# ipe5_target_db register map
Vendor: Texas Instruments
Address unit: 16 bits
Registers are 32-bit, access per field, reset 0x0 unless marked. A register's access mark holds for its fields unless they carry their own. Offsets are as the file gives them; [hi:lo] are bit positions; {n}, {i} and the like mark numbered series; 'fields as' and 'values as' point back to an identical list; <NAME> marks a mode.

## DSS (part 2 of 2) — ipxact12_to_ccs_generated
0x00 __ALL___SL2_BUF_ADDR_ORG_RASTER_TILED_LUMA_TOP — SL2 base address for RASTER OR TILED original pixels Luma location. For progressive, this MMR indicates the base address for Luma data. For interlaced frame and interlaced top field, this MMR indicates the base address for top field Luma data. For interlaced bottom field, this MMR indicates the base address for bottom field Luma data.
  [21:0] ADDR rw — SL2 Address for original pixels.
0x04 __ALL___SL2_BUF_ADDR_ORG_RASTER_TILED_CHROMA_TOP — SL2 base address for RASTER OR TILED original pixels Chroma location. For progressive, this MMR indicates the base address for Chroma data. For interlaced frame and interlaced top field, this MMR indicates the base address for top field Chroma data. For interlaced bottom field, this MMR indicates the base address for bottom field Chroma data.
  [21:0] ADDR rw — SL2 Address for original pixels.
0x08 __ALL___SL2_BUF_ADDR_ORG_RASTER_TILED_LUMA_BOT — SL2 base address for RASTER OR TILED original pixels Luma location. For progressive and interlaced field, this MMR is ignored. For interlaced frame, this MMR indicates the base address for bottom field Luma data.
  [21:0] ADDR rw — SL2 Address for original pixels.
0x0C __ALL___SL2_BUF_ADDR_ORG_RASTER_TILED_CHROMA_BOT — SL2 base address for RASTER OR TILED original pixels Chroma location. For progressive and interlaced field, this MMR is ignored. For interlaced frame, this MMR indicates the base address for bottom field Chroma data.
  [21:0] ADDR rw — SL2 Address for original pixels.
0x10 __ALL___SL2_BUF_ADDR_ORG_LUMA_TOP — SL2 base address for TILED original pixels Luma location updated by IPE5-PRE. For progressive, this MMR indicates the base address for Luma data. For interlaced frame and interlaced top field, this MMR indicates the base address for top field Luma data. For interlaced bottom field, this MMR indicates the base address for bottom field Luma data.
  [21:0] ADDR rw — SL2 Address for original pixels.
0x14 __ALL___SL2_BUF_ADDR_ORG_CHROMA_TOP — SL2 base address for TILED original pixels Chroma location updated by IPE5-PRE. For progressive, this MMR indicates the base address for Chroma data. For interlaced frame and interlaced top field, this MMR indicates the base address for top field Chroma data. For interlaced bottom field, this MMR indicates the base address for bottom field Chroma data.
  [21:0] ADDR rw — SL2 Address for original pixels.
0x18 __ALL___SL2_BUF_ADDR_ORG_LUMA_BOT — SL2 base address for TILED original pixels Luma location updated by IPE5-PRE. For progressive and interlaced field, this MMR is ignored. For interlaced frame, this MMR indicates the base address for bottom field Luma data.
  [21:0] ADDR rw — SL2 Address for original pixels.
0x1C __ALL___SL2_BUF_ADDR_ORG_CHROMA_BOT — SL2 base address for TILED original pixels Chroma location updated by IPE5-PRE. For progressive and interlaced field, this MMR is ignored. For interlaced frame, this MMR indicates the base address for bottom field Chroma data.
  [21:0] ADDR rw — SL2 Address for original pixels.
0x20 __ALL___SL2_BUF_ADDR_RECON_TOPLINE — SL2 base address for reference pixels location.
  [21:0] ADDR rw — SL2 Address for reference pixels.
0x24 __ALL___SL2_BUF_ADDR_ACTIVITYINFO — SL2 base address for writing out activity-info per MB.
  [21:0] ADDR rw — SL2 Address of activity-info location.
0x28 __ALL___SL2_BUF_ADDR_SLICEINFO_R — SL2 base address for reading initial slice info prepared by iCONT.
  [21:0] ADDR rw — SL2 Address.
0x2C __ALL___SL2_BUF_ADDR_SLICEINFO_W — SL2 base address for writing slice info.
  [21:0] ADDR rw — SL2 Address.
0x30 __ALL___SL2_BUF_ADDR_MBHDRINFO_TOP — SL2 base address for writing MB info.
  [21:0] ADDR rw — SL2 Address.
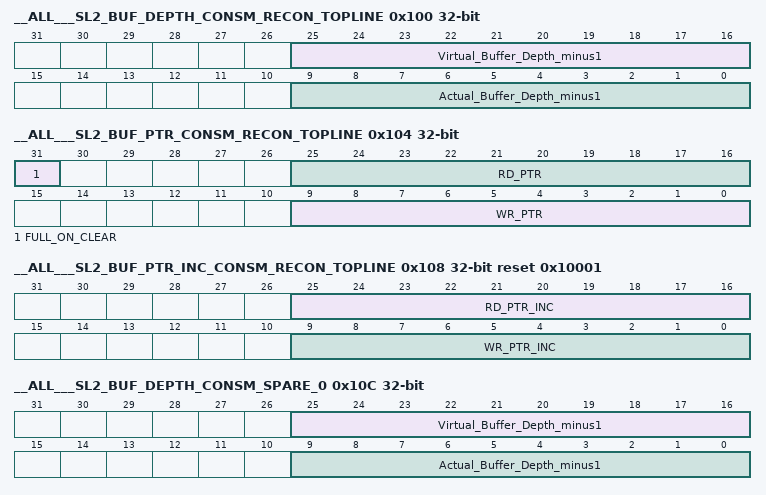
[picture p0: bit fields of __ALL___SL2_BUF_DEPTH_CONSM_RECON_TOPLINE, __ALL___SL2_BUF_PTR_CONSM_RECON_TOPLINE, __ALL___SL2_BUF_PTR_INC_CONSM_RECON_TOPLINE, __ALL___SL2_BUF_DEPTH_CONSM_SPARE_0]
0x100 __ALL___SL2_BUF_DEPTH_CONSM_RECON_TOPLINE — Actual and Virtual buffer depths for Reconstructed data BC.
  [25:16] Virtual_Buffer_Depth_minus1 rw — Indicates the Maximum pointer difference irrespective of the Actual buffer depth. But, Virtual buffer depth < Actual buffer depth. When the pointer difference is more than the configured value the wr_bc_ready gets de-asserted.
  [9:0] Actual_Buffer_Depth_minus1 rw — Number of entries in the Buffer = 1 + Actual_buffer_depth_minus1
0x104 __ALL___SL2_BUF_PTR_CONSM_RECON_TOPLINE — Read and write pointers.
  [31] FULL_ON_CLEAR rw — If start value of RD pointer = start value of WR pointer as configured in the BUF_START_PTR then 0: Buffer is empty on BC_CLR 1: Buffer is full on BC_CLR
  [25:16] RD_PTR rw — Read pointer value to be latched on BC_CLEAR.
  [9:0] WR_PTR rw — Write pointer value to be latched on BC_CLEAR.
0x108 __ALL___SL2_BUF_PTR_INC_CONSM_RECON_TOPLINE reset 0x10001 — Read and write pointer increments per access.
  [25:16] RD_PTR_INC rw — Increment value for read pointer on rd_core_busy deassertion.
  [9:0] WR_PTR_INC rw — Increment value for write pointer on wr_core_busy deassertion.
0x10C __ALL___SL2_BUF_DEPTH_CONSM_SPARE_0 — Actual and Virtual buffer depths for SPARE Consumer BC0.
  fields as __ALL___SL2_BUF_DEPTH_CONSM_RECON_TOPLINE
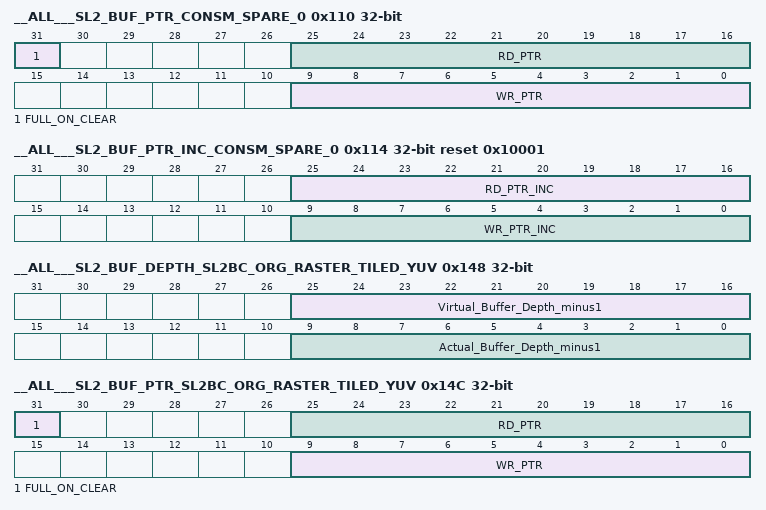
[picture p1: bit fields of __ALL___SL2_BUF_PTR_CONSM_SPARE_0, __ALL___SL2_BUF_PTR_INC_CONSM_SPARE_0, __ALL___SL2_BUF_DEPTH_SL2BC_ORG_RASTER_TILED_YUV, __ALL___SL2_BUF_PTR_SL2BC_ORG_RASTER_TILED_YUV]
0x110 __ALL___SL2_BUF_PTR_CONSM_SPARE_0 — Read and write pointers.
  fields as __ALL___SL2_BUF_PTR_CONSM_RECON_TOPLINE
0x114 __ALL___SL2_BUF_PTR_INC_CONSM_SPARE_0 reset 0x10001 — Read and write pointer increments per access.
  fields as __ALL___SL2_BUF_PTR_INC_CONSM_RECON_TOPLINE
0x118 __ALL___SL2_BUF_DEPTH_PROD_MBHDRINFO_TOP — Actual buffer depth for MB-info BC.
  [9:0] Actual_Buffer_Depth_minus1 rw — Number of entries in the Buffer = 1 + Actual_buffer_depth_minus1
0x11C __ALL___SL2_BUF_PTR_PROD_MBHDRINFO_TOP — write pointer.
  [9:0] WR_PTR rw — Write pointer value to be latched on BC_CLEAR.
0x120 __ALL___SL2_BUF_PTR_INC_PROD_MBHDRINFO_TOP reset 0x1 — Write pointer increment per access.
  [9:0] WR_PTR_INC rw — Increment value for write pointer on wr_core_busy deassertion.
0x124 __ALL___SL2_BUF_DEPTH_PROD_ACTIVITYINFO — Actual buffer depth for Activity-info BC.
  fields as __ALL___SL2_BUF_DEPTH_PROD_MBHDRINFO_TOP
0x128 __ALL___SL2_BUF_PTR_PROD_ACTIVITYINFO — Write pointer.
  [9:0] WR_PTR rw — Write pointer value to be latched on BC_CLEAR.
0x12C __ALL___SL2_BUF_PTR_INC_PROD_ACTIVITYINFO reset 0x1 — Write pointer increment per access.
  fields as __ALL___SL2_BUF_PTR_INC_PROD_MBHDRINFO_TOP
0x130 __ALL___SL2_BUF_DEPTH_PROD_SLICEINFO — Actual buffer depth for slice-info BC.
  fields as __ALL___SL2_BUF_DEPTH_PROD_MBHDRINFO_TOP
0x134 __ALL___SL2_BUF_PTR_PROD_SLICEINFO — Write pointer.
  [9:0] WR_PTR rw — Write pointer value to be latched on BC_CLEAR.
0x138 __ALL___SL2_BUF_PTR_INC_PROD_SLICEINFO reset 0x1 — Write pointer increment per access.
  fields as __ALL___SL2_BUF_PTR_INC_PROD_MBHDRINFO_TOP
0x13C __ALL___SL2_BUF_DEPTH_PROD_ORG_TILED_YUV — Actual buffer depth for original pixels BC for tiled output from IPE5.
  fields as __ALL___SL2_BUF_DEPTH_PROD_MBHDRINFO_TOP
0x140 __ALL___SL2_BUF_PTR_PROD_ORG_TILED_YUV — Write pointer.
  [9:0] WR_PTR rw — Write pointer value to be latched on BC_CLEAR.
0x144 __ALL___SL2_BUF_PTR_INC_PROD_ORG_TILED_YUV reset 0x1 — Write pointer increment per access.
  fields as __ALL___SL2_BUF_PTR_INC_PROD_MBHDRINFO_TOP
0x148 __ALL___SL2_BUF_DEPTH_SL2BC_ORG_RASTER_TILED_YUV — Actual buffer depth for original pixels RASTER_TILED buffer.
  fields as __ALL___SL2_BUF_DEPTH_CONSM_RECON_TOPLINE
0x14C __ALL___SL2_BUF_PTR_SL2BC_ORG_RASTER_TILED_YUV — Read and write pointer.
  [31] FULL_ON_CLEAR rw — If start value of RD pointer = start value of WR pointer as configured in the BUF_START_PTR then 0: Buffer is empty on BC_CLR 1: Buffer is full on BC_CLR
  [25:16] RD_PTR rw — Read pointer value to be latched on BC_CLEAR.
  [9:0] WR_PTR rw — Write pointer value.
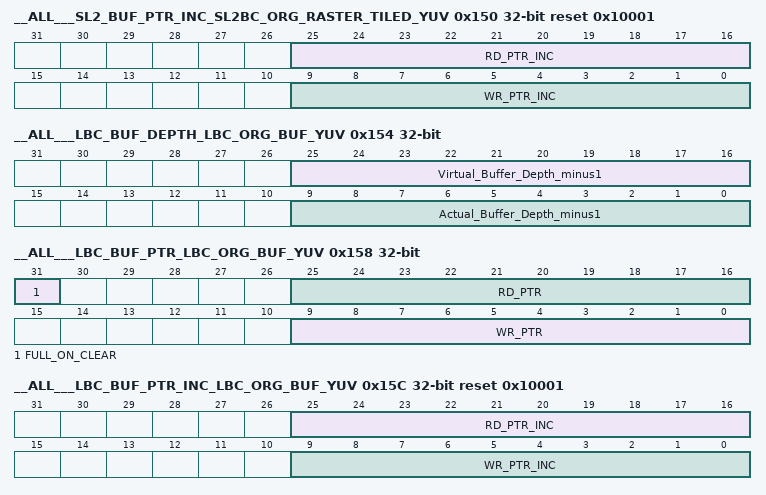
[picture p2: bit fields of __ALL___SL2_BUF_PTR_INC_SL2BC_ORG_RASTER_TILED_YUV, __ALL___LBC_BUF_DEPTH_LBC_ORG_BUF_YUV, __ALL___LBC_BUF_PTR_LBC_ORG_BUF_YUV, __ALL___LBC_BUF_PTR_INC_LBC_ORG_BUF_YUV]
0x150 __ALL___SL2_BUF_PTR_INC_SL2BC_ORG_RASTER_TILED_YUV reset 0x10001 — Read pointer increment per access.
  [25:16] RD_PTR_INC rw — Increment value for read pointer on rd_core_busy deassertion.
  [9:0] WR_PTR_INC rw — Write pointer increment value.
0x154 __ALL___LBC_BUF_DEPTH_LBC_ORG_BUF_YUV — Actual and Virtual buffer depths for original pixels LBC_ORG_BUF.
  fields as __ALL___SL2_BUF_DEPTH_CONSM_RECON_TOPLINE
0x158 __ALL___LBC_BUF_PTR_LBC_ORG_BUF_YUV — Read and write pointers.
  fields as __ALL___SL2_BUF_PTR_CONSM_RECON_TOPLINE
0x15C __ALL___LBC_BUF_PTR_INC_LBC_ORG_BUF_YUV reset 0x10001 — Read and write pointer increments per access.
  fields as __ALL___SL2_BUF_PTR_INC_CONSM_RECON_TOPLINE
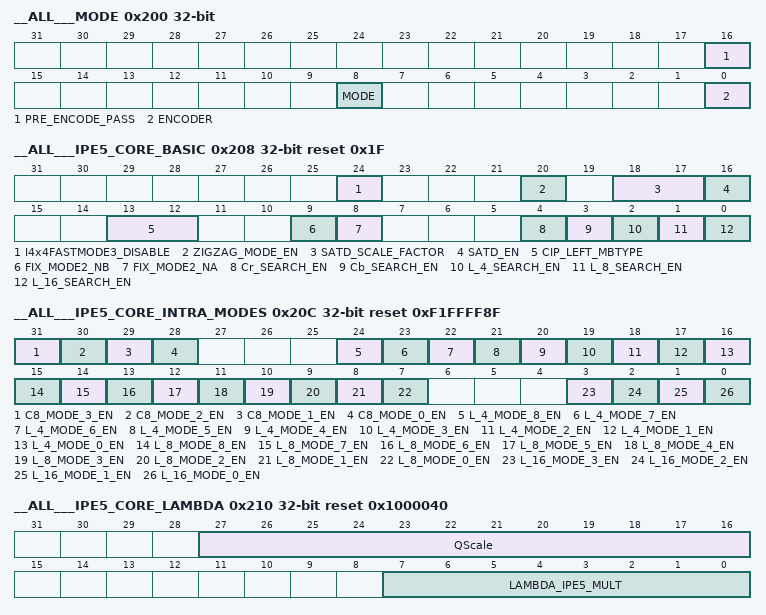
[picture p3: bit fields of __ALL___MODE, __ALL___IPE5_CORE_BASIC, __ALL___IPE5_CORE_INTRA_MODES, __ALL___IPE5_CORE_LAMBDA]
0x200 __ALL___MODE — IPE5 Mode Register.
  [16] PRE_ENCODE_PASS rw — Pre-Encode pass Mode enable. 0 : Full Encode Pass 1 : Pre-Encode Pass
  [8] MODE rw — 1 => H.241 0 => Normal mode
  [0] ENCODER rw — 1 => Encoder mode 0 => Decoder mode (IPE5 is shut down)
0x204 __ALL___CODEC_TYPE — IPE5 Codec type register.
  [3:0] CODEC_TYPE rw — 0 => H.264 1 => SVC 2 => VP8
0x208 __ALL___IPE5_CORE_BASIC reset 0x1F — IPE5 Basic Settings Register for IPE5-CORE.
  [24] I4x4FASTMODE3_DISABLE rw — 0 => 4X4 Mode3 is optimized for faster MB processing. 1 => 4x4 Mode3 optimization is disabled. Slower MB processing.
  [20] ZIGZAG_MODE_EN rw — ZIGZAG Mode of MB processing in frame. 0 : Use raster scan order. This is defualt. 1 : Use zig-zag scan order for MB processsing.
  [18:17] SATD_SCALE_FACTOR rw — Support a flexible scaling factors for SATD value. 0 – no scaling 1 – right shift by 1 2 – right shift by 2 3 – right shift by 3
  [16] SATD_EN rw — Enable SATD based best mode selection. 0 : Only SAD based best mode selection, which is default 1 : SATD based best mode selection
  [13:12] CIP_LEFT_MBTYPE rw — Indicates the mb_type of left MB. This data is valid only in case of constrained intra prediction. 00 : Left mb_type is same as TOP LEFT Macroblock mb_type. 01 : Left mb_type is assumed intra 10 : Left mb_type is assumed inter 11 : Left mb_type is median of top, top_left and (top_left-1) mb_types
  [9] FIX_MODE2_NB rw — Mode of Top block to current MB. 0 : Use mode from the MB-info of top MB, which is provided by CALC 1 : Used fixed mode2 (DC)
  [8] FIX_MODE2_NA rw — Mode of left block to current MB. 0 : Use mode from the MB-info of left MB, which is internally stored 1 : Used fixed mode2 (DC)
  [4] Cr_SEARCH_EN rw — Enable SIP to search Cr. 0 : Cr component is NOT searched 0 : Cr component is searched for best modes evaluation
  [3] Cb_SEARCH_EN rw — Enable SIP to search Cb. 0 : Cb component is NOT searched 0 : Cb component is searched for best modes evaluation
  [2] L_4_SEARCH_EN rw — Enable SIP to search in 4X4 Partition type. 0 : 4X4 Partition type is NOT searched 0 : 4X4 Partition type is searched for best modes and partition type evaluation
  [1] L_8_SEARCH_EN rw — Enable SIP to search in 8X8 Partition type. 0 : 8X8 Partition type is NOT searched 0 : 8X8 Partition type is searched for best modes and partition type evaluation
  [0] L_16_SEARCH_EN rw — Enable SIP to search in 16X16 Partition type. 0 : 16X16 Partition type is NOT searched 0 : 16X16 Partition type is searched for best modes and partition type evaluation
0x20C __ALL___IPE5_CORE_INTRA_MODES reset 0xF1FFFF8F — IPE5 Intra modes control register for Luma and Chroma.
  [31] C8_MODE_3_EN rw — Enable MODE 3 (Planer) for Chroma. 0 : MODE 3 is disabled. 1 : MODE 3 is enabled.
  [30] C8_MODE_2_EN rw — Enable MODE 2 (Vertical) for Chroma. 0 : MODE 2 is disabled. 1 : MODE 2 is enabled.
  [29] C8_MODE_1_EN rw — Enable MODE 1 (Horizontal) for Chroma. 0 : MODE 1 is disabled. 1 : MODE 1 is enabled.
  [28] C8_MODE_0_EN rw — Enable MODE 0 (DC) for Chroma. 0/1 : MODE 0 is always enabled by default independent of value of this bit.
  [24] L_4_MODE_8_EN rw — Enable MODE 8 (Horizontal Up) for Luma 4X4 Partition. 0 : MODE 8 is disabled. 1 : MODE 8 is enabled.
  [23] L_4_MODE_7_EN rw — Enable MODE 7 (Vertical Left) for Luma 4X4 Partition. 0 : MODE 7 is disabled. 1 : MODE 7 is enabled.
  [22] L_4_MODE_6_EN rw — Enable MODE 6 (Horizontal Down) for Luma 4X4 Partition. 0 : MODE 6 is disabled. 1 : MODE 6 is enabled.
  [21] L_4_MODE_5_EN rw — Enable MODE 5 (Vertical Right) for Luma 4X4 Partition. 0 : MODE 5 is disabled. 1 : MODE 5 is enabled.
  [20] L_4_MODE_4_EN rw — Enable MODE 4 (Diagonal Down Right) for Luma 4X4 Partition. 0 : MODE 4 is disabled. 1 : MODE 4 is enabled.
  [19] L_4_MODE_3_EN rw — Enable MODE 3 (Diagonal Down Left) for Luma 4X4 Partition. 0 : MODE 3 is disabled. 1 : MODE 3 is enabled.
  [18] L_4_MODE_2_EN rw — Enable MODE 2 (DC) for Luma 4X4 Partition. 0 : MODE 2 is disabled. 1 : MODE 2 is enabled.
  [17] L_4_MODE_1_EN rw — Enable MODE 1 (Horizontal) for Luma 4X4 Partition. 0 : MODE 1 is disabled. 1 : MODE 1 is enabled.
  [16] L_4_MODE_0_EN rw — Enable MODE 0 (Vertical) for Luma 4X4 Partition. 0 : MODE 0 is disabled. 1 : MODE 0 is enabled.
  [15] L_8_MODE_8_EN rw — Enable MODE 8 (Horizontal Up) for Luma 8X8 Partition. 0 : MODE 8 is disabled. 1 : MODE 8 is enabled.
  [14] L_8_MODE_7_EN rw — Enable MODE 7 (Vertical Left) for Luma 8X8 Partition. 0 : MODE 7 is disabled. 1 : MODE 7 is enabled.
  [13] L_8_MODE_6_EN rw — Enable MODE 6 (Horizontal Down) for Luma 8X8 Partition. 0 : MODE 6 is disabled. 1 : MODE 6 is enabled.
  [12] L_8_MODE_5_EN rw — Enable MODE 5 (Vertical Right) for Luma 8X8 Partition. 0 : MODE 5 is disabled. 1 : MODE 5 is enabled.
  [11] L_8_MODE_4_EN rw — Enable MODE 4 (Diagonal Down Right) for Luma 8X8 Partition. 0 : MODE 4 is disabled. 1 : MODE 4 is enabled.
  [10] L_8_MODE_3_EN rw — Enable MODE 3 (Diagonal Down Left) for Luma 8X8 Partition. 0 : MODE 3 is disabled. 1 : MODE 3 is enabled.
  [9] L_8_MODE_2_EN rw — Enable MODE 2 (DC) for Luma 8X8 Partition. 0 : MODE 2 is disabled. 1 : MODE 2 is enabled.
  [8] L_8_MODE_1_EN rw — Enable MODE 1 (Horizontal) for Luma 8X8 Partition. 0 : MODE 1 is disabled. 1 : MODE 1 is enabled.
  [7] L_8_MODE_0_EN rw — Enable MODE 0 (Vertical) for Luma 8X8 Partition. 0 : MODE 0 is disabled. 1 : MODE 0 is enabled.
  [3] L_16_MODE_3_EN rw — Enable MODE 3 (Planer) for Luma 16X16 Partition. 0 : MODE 3 is disabled. 1 : MODE 3 is enabled.
  [2] L_16_MODE_2_EN rw — Enable MODE 2 (DC) for Luma 16X16 Partition. 0/1 : MODE 2 is always enabled by default independent of value of this bit.
  [1] L_16_MODE_1_EN rw — Enable MODE 1 (Horizontal) for Luma 16X16 Partition. 0 : MODE 1 is disabled. 1 : MODE 1 is enabled.
  [0] L_16_MODE_0_EN rw — Enable MODE 0 (Vertical) for Luma 16X16 Partition. 0 : MODE 0 is disabled. 1 : MODE 0 is enabled.
0x210 __ALL___IPE5_CORE_LAMBDA reset 0x1000040 — Parameters to control IPE5_LAMBDA value.
  [27:16] QScale rw — Picture level QScale to be programmed by ICONT at the start of picture. Expressed in Q4 format.
  [7:0] LAMBDA_IPE5_MULT rw — 8-bit unsigned multiplication factor.
0x214 __ALL___IPE5_CORE_PRECISE_COST reset 0x40 — IPE5 Precise cost parameter for computing Precise overhead penalty for 4X4 and 8X8 Luma partition types.
  [7:0] NPREC rw — User defined 8-bit value expressed in Q4.4 format and range is [0, 15.9375]
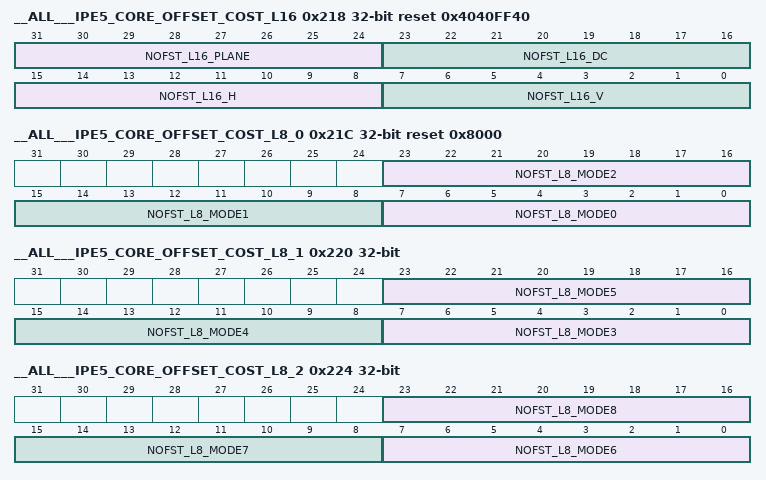
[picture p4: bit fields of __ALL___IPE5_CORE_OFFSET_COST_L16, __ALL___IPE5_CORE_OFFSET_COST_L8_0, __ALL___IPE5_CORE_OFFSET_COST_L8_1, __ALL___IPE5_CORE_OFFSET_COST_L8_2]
0x218 __ALL___IPE5_CORE_OFFSET_COST_L16 rw reset 0x4040FF40 — IPE5 Offset cost parameter for computing offset value for Luma 16X16 Partition type. The 8-bit value is expressed in Q4.4 format.
  [31:24] NOFST_L16_PLANE — Offset cost parameter for Luma 16X16 partition type and Planer mode.
  [23:16] NOFST_L16_DC — Offset cost parameter for Luma 16X16 partition type and DC mode.
  [15:8] NOFST_L16_H — Offset cost parameter for Luma 16X16 partition type and horizontal mode.
  [7:0] NOFST_L16_V — Offset cost parameter for Luma 16X16 partition type and Vertical mode.
0x21C __ALL___IPE5_CORE_OFFSET_COST_L8_0 reset 0x8000 — IPE5 Offset cost parameter for computing offset value for Luma 8X8 Partition type and mode 0, 1 and 2. The 8-bit value is expressed in Q4.4 format.
  [23:16] NOFST_L8_MODE2 rw — Offset cost parameter for Luma 8X8 partition type and DC mode.
  [15:8] NOFST_L8_MODE1 rw — Offset cost parameter for Luma 8X8 partition type and Horizontal mode.
  [7:0] NOFST_L8_MODE0 rw — Offset cost parameter for Luma 8X8 partition type and Vertical mode.
0x220 __ALL___IPE5_CORE_OFFSET_COST_L8_1 — IPE5 Offset cost parameter for computing offset value for Luma 8X8 Partition type and modes 3, 4 and 5. The 8-bit value is expressed in Q4.4 format.
  [23:16] NOFST_L8_MODE5 rw — Offset cost parameter for Luma 8X8 partition type and mode 5.
  [15:8] NOFST_L8_MODE4 rw — Offset cost parameter for Luma 8X8 partition type and mode 4.
  [7:0] NOFST_L8_MODE3 rw — Offset cost parameter for Luma 8X8 partition type and mode 3.
0x224 __ALL___IPE5_CORE_OFFSET_COST_L8_2 — IPE5 Offset cost parameter for computing offset value for Luma 8X8 Partition type and modes 6, 7 and 8. The 8-bit value is expressed in Q4.4 format.
  [23:16] NOFST_L8_MODE8 rw — Offset cost parameter for Luma 8X8 partition type and mode 8.
  [15:8] NOFST_L8_MODE7 rw — Offset cost parameter for Luma 8X8 partition type and mode 7.
  [7:0] NOFST_L8_MODE6 rw — Offset cost parameter for Luma 8X8 partition type and mode 6.
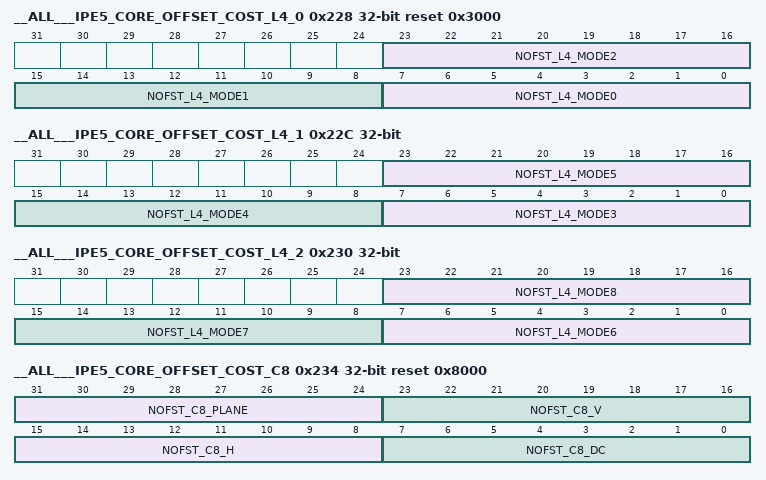
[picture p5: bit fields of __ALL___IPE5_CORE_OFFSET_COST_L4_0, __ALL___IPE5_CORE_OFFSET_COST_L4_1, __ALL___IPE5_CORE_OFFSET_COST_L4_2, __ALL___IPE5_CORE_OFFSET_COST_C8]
0x228 __ALL___IPE5_CORE_OFFSET_COST_L4_0 reset 0x3000 — IPE5 Offset cost parameter for computing offset value for Luma 4X4 Partition type and mode 0, 1 and 2. The 8-bit value is expressed in Q4.4 format.
  [23:16] NOFST_L4_MODE2 rw — Offset cost parameter for Luma 4X4 partition type and DC mode.
  [15:8] NOFST_L4_MODE1 rw — Offset cost parameter for Luma 4X4 partition type and Horizontal mode.
  [7:0] NOFST_L4_MODE0 rw — Offset cost parameter for Luma 4X4 partition type and Vertical mode.
0x22C __ALL___IPE5_CORE_OFFSET_COST_L4_1 — IPE5 Offset cost parameter for computing offset value for Luma 4X4 Partition type and mode 3, 4 and 5. The 8-bit value is expressed in Q4.4 format.
  [23:16] NOFST_L4_MODE5 rw — Offset cost parameter for Luma 4X4 partition type and mode5.
  [15:8] NOFST_L4_MODE4 rw — Offset cost parameter for Luma 4X4 partition type and mode4.
  [7:0] NOFST_L4_MODE3 rw — Offset cost parameter for Luma 4X4 partition type and mode3.
0x230 __ALL___IPE5_CORE_OFFSET_COST_L4_2 — IPE5 Offset cost parameter for computing offset value for Luma 4X4 Partition type and mode 6, 7 and 8. The 8-bit value is expressed in Q4.4 format.
  [23:16] NOFST_L4_MODE8 rw — Offset cost parameter for Luma 4X4 partition type and mode8.
  [15:8] NOFST_L4_MODE7 rw — Offset cost parameter for Luma 4X4 partition type and mode7.
  [7:0] NOFST_L4_MODE6 rw — Offset cost parameter for Luma 4X4 partition type and mode6.
0x234 __ALL___IPE5_CORE_OFFSET_COST_C8 rw reset 0x8000 — IPE5 Offset cost parameter for computing offset value for Chroma modes. The 8-bit value is expressed in Q4.4 format.
  [31:24] NOFST_C8_PLANE — Offset cost parameter for Chroma Planer mode.
  [23:16] NOFST_C8_V — Offset cost parameter for Chroma Vertical mode.
  [15:8] NOFST_C8_H — Offset cost parameter for Chroma Horizontal mode.
  [7:0] NOFST_C8_DC — Offset cost parameter for Chroma DC mode.
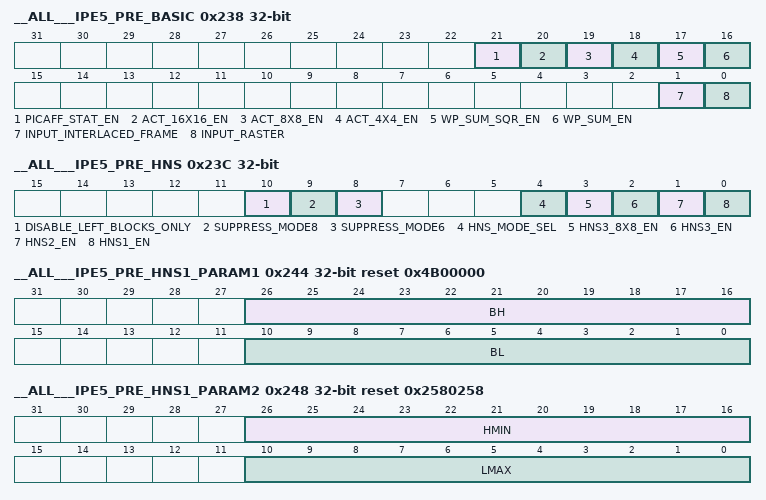
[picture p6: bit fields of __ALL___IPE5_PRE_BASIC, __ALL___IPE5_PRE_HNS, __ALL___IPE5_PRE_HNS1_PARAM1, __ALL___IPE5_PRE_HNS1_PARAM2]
0x238 __ALL___IPE5_PRE_BASIC — IPE5 Basic Settings Register for PREPROCESSOR.
  [21] PICAFF_STAT_EN rw — Enable PICAFF statistics accumulation step. This is valid only in pre-processing pass. 0: PicAFF support disabled. Input data is assumed to be progressive OR seperate fields. 1: PicAFF support enabled. Input data is assumed to be interlaced frame.
  [20] ACT_16X16_EN rw — 0 : Activity 16x16 NOT updated in activity-info. 1 : Activity 16x16 updated in activity-info. For funtions which need activity information like RC and HNS, the internal activity computation is enabled but value is not updated in activity-info if this bit is not set.
  [19] ACT_8X8_EN rw — 0 : Activity 8x8 NOT updated in activity-info. 1 : Activity 8x8 updated in activity-info. For funtions which need activity information like RC and HNS, the internal activity computation is enabled but value is not updated in activity-info if this bit is not set.
  [18] ACT_4X4_EN rw — 0 : Activity 4x4 NOT updated in activity-info. 1 : Activity 4x4 updated in activity-info. For funtions which need activity information like RC and HNS, the internal activity computation is enabled but value is not updated in activity-info if this bit is not set.
  [17] WP_SUM_SQR_EN rw — Enable computation of SUM of SQUARE of pixels in MB for Weighted Prediction statistics 0 : SUM of SQUARES computation NOT enabled 1 : SUM of SQUARES computation enabled
  [16] WP_SUM_EN rw — Enable computation of SUM of pixels in MB for Weighted Prediction statistics 0 : SUM computation NOT enabled 1 : SUM computation enabled
  [1] INPUT_INTERLACED_FRAME rw — Control bit to indicate that the input data is interlaced frame for pre-encode pass. 0 : Input is Progressive OR seperate Fields (top/bottom) 1 : Input is interlaced frame
  [0] INPUT_RASTER rw — Indicates whether the input original pixels in SL2 is tiled or raster. 0 : Input is TILED. 1 : Input is RASTER.
0x23C __ALL___IPE5_PRE_HNS — IPE5 Control register for Horizontal Noise Suppresion.
  [10] DISABLE_LEFT_BLOCKS_ONLY rw — Control bit to choose the set of blocks on which horizontal modes are disabled. 0 : Disable horizontal modes for all blocks. 1 : Disable horizontal modes for left blocks only.
  [9] SUPPRESS_MODE8 rw — Control bit to enable suppression of MODE8 in case HNS indicates suppression. 0 : MODE8 Allowed even if HNS inidcates suppression. 1 : MODE8 Suppressed in case HNS indicates suppression.
  [8] SUPPRESS_MODE6 rw — Control bit to enable suppression of MODE6 in case HNS indicates suppression. 0 : MODE6 Allowed even if HNS inidcates suppression. 1 : MODE6 Suppressed in case HNS indicates suppression.
  [4] HNS_MODE_SEL rw — Control bit to choose the algorithms of HNS (Activity and partition type based). 1 : Horizontal modes is suppressed if all the enabled algo’s indicate suppression. 0 : Horizontal modes is suppressed if either of the enabled algo indicates suppression.
  [3] HNS3_8X8_EN rw — Control bit to enable HNS when left MB partition type is 8X8. 0 : Disable Partition type based HNS if left MB partition type is 8X8. 1 : Enable Partition type based HNS if left MB partition type is 8X8.
  [2] HNS3_EN rw — Control to enable the Neighouring MB partition type based HNS (Type 3) 0 : Neighouring MB partition type based HNS is disabled. 1 : Neighouring MB partition type based HNS is enabled.
  [1] HNS2_EN rw — Control to enable the activity based HNS (Type 2) 0 : Activity based HNS is disabled. 1 : Activity based HNS is enabled.
  [0] HNS1_EN rw — Control to enable the activity based HNS (Type 1, similar to IPE53) 0 : Activity based HNS is disabled. 1 : Activity based HNS is enabled.
0x240 __ALL___IPE5_PRE_HNS1_PARAM0 reset 0x1E — IPE5 Control register for Horizontal Noise Suppresion1.
  [6:0] A rw — 7-bit Mutiplier for QScale in HNS1 equation
0x244 __ALL___IPE5_PRE_HNS1_PARAM1 reset 0x4B00000 — IPE5 Control register for Horizontal Noise Suppresion1.
  [26:16] BH rw — 11-bit BH parameter as in equation for HNS1.
  [10:0] BL rw — 11-bit BL parameter as in equation for HNS1.
0x248 __ALL___IPE5_PRE_HNS1_PARAM2 reset 0x2580258 — IPE5 Control register for Horizontal Noise Suppresion1.
  [26:16] HMIN rw — Level setting for H_threshold as in equation for HNS1.
  [10:0] LMAX rw — Level setting for L_threshold as in equation for HNS1.
0x24C __ALL___IPE5_PRE_HNS2_PARAM0 reset 0x8 — IPE5 Control register for Horizontal Noise Suppresion 2.
  [7:0] MULT_TH rw — 8-bit Multiplier threshold factor to be applied for HNS2 (New Activity based HNS)
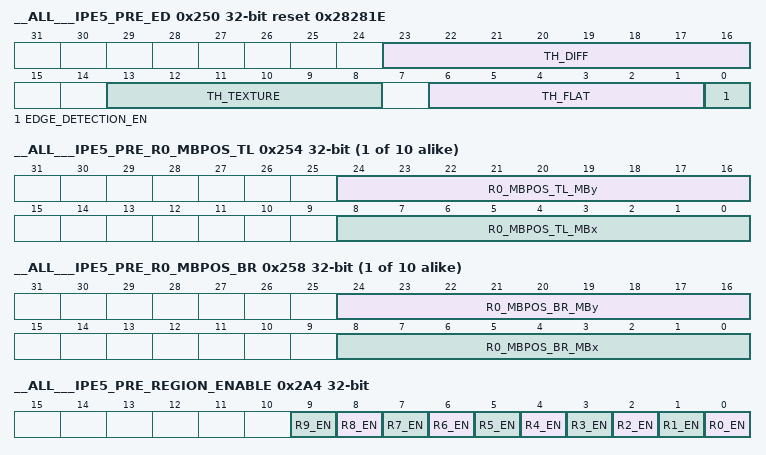
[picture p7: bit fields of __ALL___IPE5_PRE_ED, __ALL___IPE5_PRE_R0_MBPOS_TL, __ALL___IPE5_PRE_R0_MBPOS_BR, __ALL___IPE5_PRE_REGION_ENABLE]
0x250 __ALL___IPE5_PRE_ED reset 0x28281E — IPE5 MMR to control the edge based text detection algorithm.
  [23:16] TH_DIFF rw — Threshold value to compare the maximum gradient per pixel. The gradient is the maximum value of pixel difference in either horizontal, vertical or diagonal direction.
  [13:8] TH_TEXTURE rw — Pre-programmed value to for texture threshold to compare in a 8X8 block.
  [6:1] TH_FLAT rw — Pre-programmed value to for text threshold to compare in a 8X8 block.
  [0] EDGE_DETECTION_EN rw — Enable Text Detection Algorithm 0 : NOT enabled 1 : enabled
{0x254+8i} __ALL___IPE5_PRE_R{i}_MBPOS_TL (i=0..9) — Register for Region {i}. Position information for Left and Top MB in the Region {i}.
  [24:16] R{i}_MBPOS_TL_MBy rw — Top MB position in Region {i}.
  [8:0] R{i}_MBPOS_TL_MBx rw — Left MB position in Region {i}. 9-bits for 8KX8K frame support.
{0x258+8i} __ALL___IPE5_PRE_R{i}_MBPOS_BR (i=0..9) — Register for Region {i}. Position information for Right and Bottom MB in the Region {i}.
  [24:16] R{i}_MBPOS_BR_MBy rw — Bottom MB position in Region {i}.
  [8:0] R{i}_MBPOS_BR_MBx rw — Right MB position in Region {i}. 9-bits for 8KX8K frame support.
0x2A4 __ALL___IPE5_PRE_REGION_ENABLE — Region enable control register.
  [n] R{n}_EN rw (n=0..9) — 1=> Region{n} is valid/Enabled. 0=> Region{n} is invalid/not enabled.
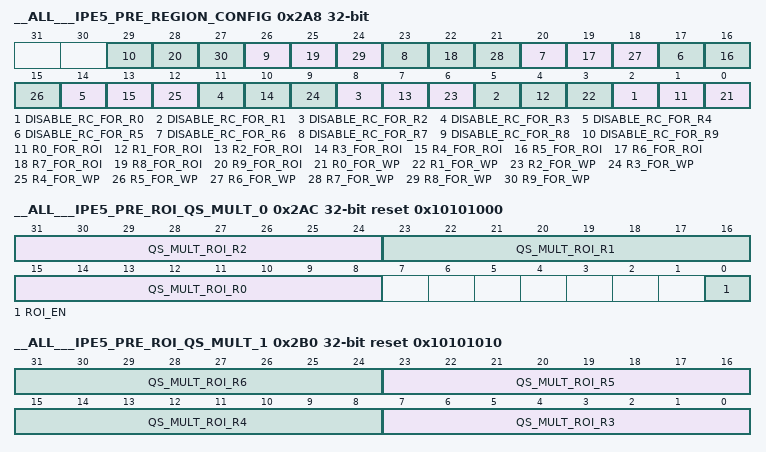
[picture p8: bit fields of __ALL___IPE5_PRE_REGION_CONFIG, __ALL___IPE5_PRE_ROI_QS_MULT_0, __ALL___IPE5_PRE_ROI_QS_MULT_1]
0x2A8 __ALL___IPE5_PRE_REGION_CONFIG — Region feature control register.
  [3n+2] DISABLE_RC_FOR_R{n} rw (n=0..9) — 0=> Rate Control for the region is enabled if RC_EN=1 1=> Rate Control for the region is disabled even if RC_EN =1
  [3n+1] R{n}_FOR_ROI rw (n=0..9) — 1=> Region{n} is used for ROI. 0=> Region{n} is not used for ROI.
  [3n] R{n}_FOR_WP rw (n=0..9) — 1=> Region{n} is used for WP. 0=> Region{n} is not used for WP.
0x2AC __ALL___IPE5_PRE_ROI_QS_MULT_0 reset 0x10101000 — ROI enable and Multiplication Factors to modify the row level Qscale with. The factors are in Q4.4 format. modifiedQscale = (baseRowQscale * QS_MULT_ROI_Rx) >> 4.
  [31:24] QS_MULT_ROI_R2 rw — 8-bit Qscale multiplication factor.
  [23:16] QS_MULT_ROI_R1 rw — 8-bit Qscale multiplication factor.
  [15:8] QS_MULT_ROI_R0 rw — 8-bit Qscale multiplication factor.
  [0] ROI_EN rw — 0=> ROI is disabled. 1=> ROI is enabled.
0x2B0 __ALL___IPE5_PRE_ROI_QS_MULT_1 rw reset 0x10101010 — Multiplication Factors to modify the row level Qscale with. The factors are in Q4.4 format. modifiedQscale = (baseRowQscale * QS_MULT_ROI_Rx) >> 4.
  [8n-17:8n-24] QS_MULT_ROI_R{n} (n=3..6) — 8-bit Qscale multiplication factor.
